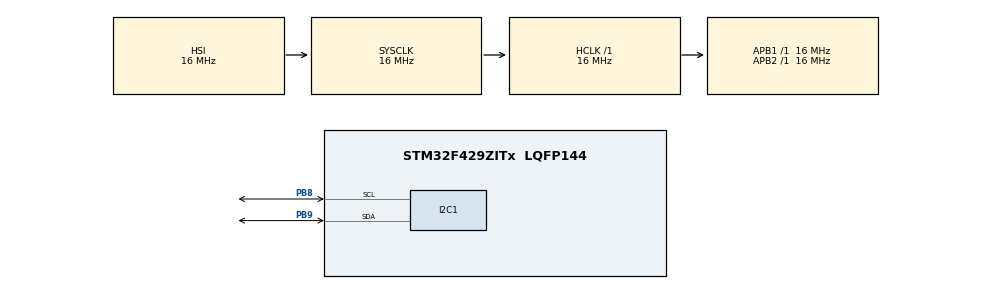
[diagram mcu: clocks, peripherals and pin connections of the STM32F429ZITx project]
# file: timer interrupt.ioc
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I2C1.I2C_Mode=I2C_Fast
Mcu.Family=STM32F4
Mcu.Name=STM32F429ZITx
Mcu.Package=LQFP144
NVIC.PriorityGroup=NVIC_PRIORITYGROUP_4
NVIC.TIM2_IRQn=true\:0\:0\:false\:false\:true\:true\:true\:true
PA13.Mode=Serial_Wire
PA13.Signal=SYS_JTMS-SWDIO
PA14.Mode=Serial_Wire
PA14.Signal=SYS_JTCK-SWCLK
PB8.Mode=I2C
PB8.Signal=I2C1_SCL
PB9.Mode=I2C
PB9.Signal=I2C1_SDA
ProjectManager.HeapSize=0x200
ProjectManager.StackSize=0x400
ProjectManager.TargetToolchain=STM32CubeIDE
RCC.AHBFreq_Value=16000000
RCC.APB1Freq_Value=16000000
RCC.APB2Freq_Value=16000000
RCC.APB2TimFreq_Value=16000000
RCC.CortexFreq_Value=16000000
RCC.HSE_VALUE=25000000
RCC.HSI_VALUE=16000000
RCC.LSE_VALUE=32768
RCC.SYSCLKFreq_VALUE=16000000
RCC.VCOOutputFreq_Value=192000000
TIM2.Period=10000 - 1
TIM2.Prescaler=1600 - 1
VP_TIM2_VS_ClockSourceINT.Mode=Internal
board=custom

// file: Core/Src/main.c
/* USER CODE BEGIN Header */
/**
  ******************************************************************************
  * @file           : main.c
  * @brief          : Main program body
  ******************************************************************************
  * @attention
  *
  * Copyright (c) 2024 STMicroelectronics.
  * All rights reserved.
  *
  * This software is licensed under terms that can be found in the LICENSE file
  * in the root directory of this software component.
  * If no LICENSE file comes with this software, it is provided AS-IS.
  *
  ******************************************************************************
  */
/* USER CODE END Header */
#include "main.h"
#include "i2c.h"
#include "tim.h"
#include "gpio.h"

/* USER CODE BEGIN Includes */
#include "oled.h"
/* USER CODE END Includes */

void SystemClock_Config(void);

/* USER CODE BEGIN 0 */
uint32_t counterNum = 0;
/* USER CODE END 0 */

int main(void)
{

  /* MCU Configuration--------------------------------------------------------*/

  /* Reset of all peripherals, Initializes the Flash interface and the Systick. */
  HAL_Init();

  /* Configure the system clock */
  SystemClock_Config();

  /* Initialize all configured peripherals */
  MX_GPIO_Init();
  MX_I2C1_Init();
  MX_TIM2_Init();
  /* USER CODE BEGIN 2 */
  HAL_Delay(20);
  OLED_Init();
  __HAL_TIM_CLEAR_FLAG(&htim2, TIM_FLAG_UPDATE);
  HAL_TIM_Base_Start_IT(&htim2);

  /* USER CODE END 2 */

  /* Infinite loop */
  /* USER CODE BEGIN WHILE */
  while (1)
  {
	  OLED_ShowNum_Fill_Zero(30, 20, 5, counterNum, &Font_11x18);
	  HAL_Delay(10);
    /* USER CODE END WHILE */

  }
}

void SystemClock_Config(void)
{
  RCC_OscInitTypeDef RCC_OscInitStruct = {0};
  RCC_ClkInitTypeDef RCC_ClkInitStruct = {0};

  /** Configure the main internal regulator output voltage
  */
  __HAL_RCC_PWR_CLK_ENABLE();
  __HAL_PWR_VOLTAGESCALING_CONFIG(PWR_REGULATOR_VOLTAGE_SCALE3);

  /** Initializes the RCC Oscillators according to the specified parameters
  * in the RCC_OscInitTypeDef structure.
  */
  RCC_OscInitStruct.OscillatorType = RCC_OSCILLATORTYPE_HSI;
  RCC_OscInitStruct.HSIState = RCC_HSI_ON;
  RCC_OscInitStruct.HSICalibrationValue = RCC_HSICALIBRATION_DEFAULT;
  RCC_OscInitStruct.PLL.PLLState = RCC_PLL_NONE;
  if (HAL_RCC_OscConfig(&RCC_OscInitStruct) != HAL_OK)
  {
    Error_Handler();
  }

  /** Initializes the CPU, AHB and APB buses clocks
  */
  RCC_ClkInitStruct.ClockType = RCC_CLOCKTYPE_HCLK|RCC_CLOCKTYPE_SYSCLK
                              |RCC_CLOCKTYPE_PCLK1|RCC_CLOCKTYPE_PCLK2;
  RCC_ClkInitStruct.SYSCLKSource = RCC_SYSCLKSOURCE_HSI;
  RCC_ClkInitStruct.AHBCLKDivider = RCC_SYSCLK_DIV1;
  RCC_ClkInitStruct.APB1CLKDivider = RCC_HCLK_DIV1;
  RCC_ClkInitStruct.APB2CLKDivider = RCC_HCLK_DIV1;

  if (HAL_RCC_ClockConfig(&RCC_ClkInitStruct, FLASH_LATENCY_0) != HAL_OK)
  {
    Error_Handler();
  }
}

/* USER CODE BEGIN 4 */
void HAL_TIM_PeriodElapsedCallback(TIM_HandleTypeDef* htim){
	if(htim->Instance == htim2.Instance){
		counterNum++;
	}
}
/* USER CODE END 4 */

void Error_Handler(void)
{
  __disable_irq();
  while (1)
  {
  }
}
